# STM32H7A3xx register map
File version: 1.0
Registers are 32-bit, access not given, reset 0x0 unless marked. A register's access mark holds for its fields unless they carry their own. Offsets are from the block's base; [hi:lo] are bit positions; {n}, {i} and the like mark numbered series.

## OPAMP1
Base 0x40009000
Same registers: OPAMP2 0x40009010
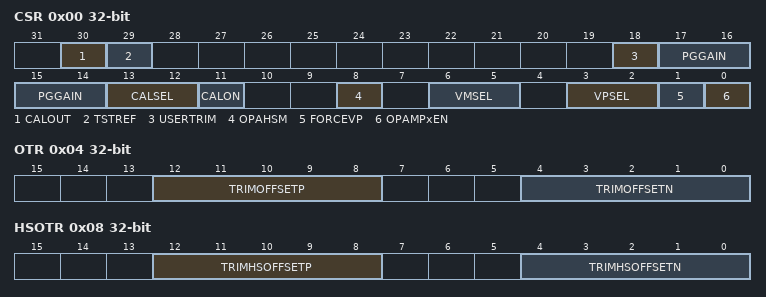
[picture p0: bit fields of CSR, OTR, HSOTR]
0x00 CSR
  [30] CALOUT, [29] TSTREF, [18] USERTRIM, [17:14] PGGAIN, [13:12] CALSEL, [11] CALON, [8] OPAHSM, [6:5] VMSEL, [3:2] VPSEL, [1] FORCEVP, [0] OPAMPxEN
0x04 OTR
  [12:8] TRIMOFFSETP, [4:0] TRIMOFFSETN
0x08 HSOTR
  [12:8] TRIMHSOFFSETP, [4:0] TRIMHSOFFSETN

## MDIOS
Base 0x40009400
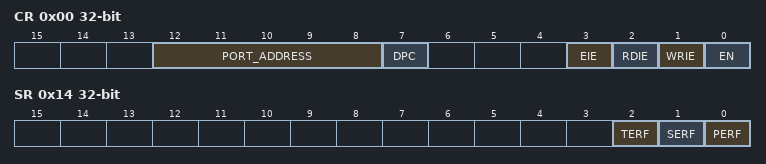
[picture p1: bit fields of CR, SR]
0x00 CR
  [12:8] PORT_ADDRESS, [7] DPC, [3] EIE, [2] RDIE, [1] WRIE, [0] EN
0x04 WRFR
0x08 CWRFR
0x0C RDFR
0x10 CRDFR
0x14 SR
  [2] TERF, [1] SERF, [0] PERF
0x18 CLRFR
{0x100+4i} DINR{i} (i=0..31)
{0x180+4i} DOUTR{i} (i=0..31)

## FDCAN1
Base 0x4000A000
Same registers: FDCAN2 0x4000A400
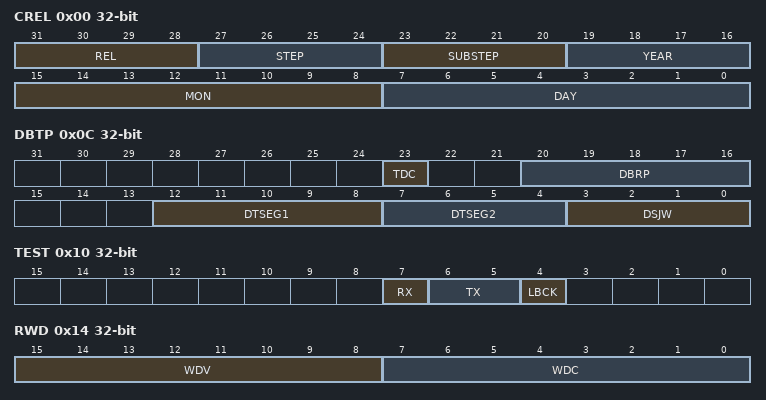
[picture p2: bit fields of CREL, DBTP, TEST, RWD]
0x00 CREL
  [31:28] REL, [27:24] STEP, [23:20] SUBSTEP, [19:16] YEAR, [15:8] MON, [7:0] DAY
0x04 ENDN
  [31:0] ETV
0x0C DBTP
  [23] TDC, [20:16] DBRP, [12:8] DTSEG1, [7:4] DTSEG2, [3:0] DSJW
0x10 TEST
  [7] RX, [6:5] TX, [4] LBCK
0x14 RWD
  [15:8] WDV, [7:0] WDC
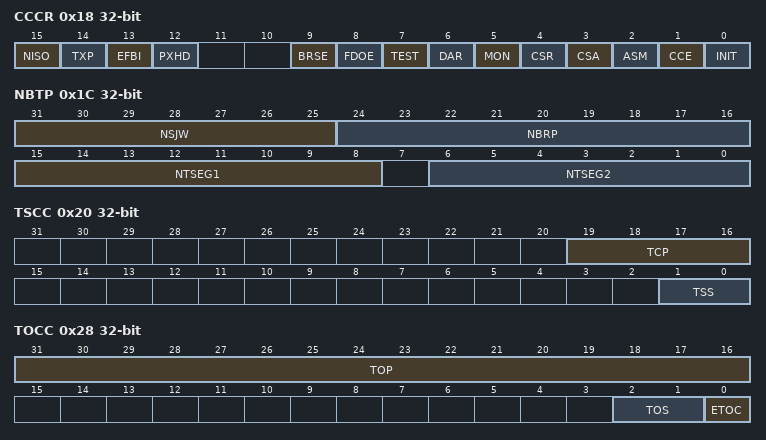
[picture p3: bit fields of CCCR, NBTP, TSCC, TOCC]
0x18 CCCR
  [15] NISO, [14] TXP, [13] EFBI, [12] PXHD, [9] BRSE, [8] FDOE, [7] TEST, [6] DAR, [5] MON, [4] CSR, [3] CSA, [2] ASM, [1] CCE, [0] INIT
0x1C NBTP
  [31:25] NSJW, [24:16] NBRP, [15:8] NTSEG1, [6:0] NTSEG2
0x20 TSCC
  [19:16] TCP, [1:0] TSS
0x24 TSCV
  [15:0] TSC
0x28 TOCC
  [31:16] TOP, [2:1] TOS, [0] ETOC
0x2C TOCV
  [15:0] TOC
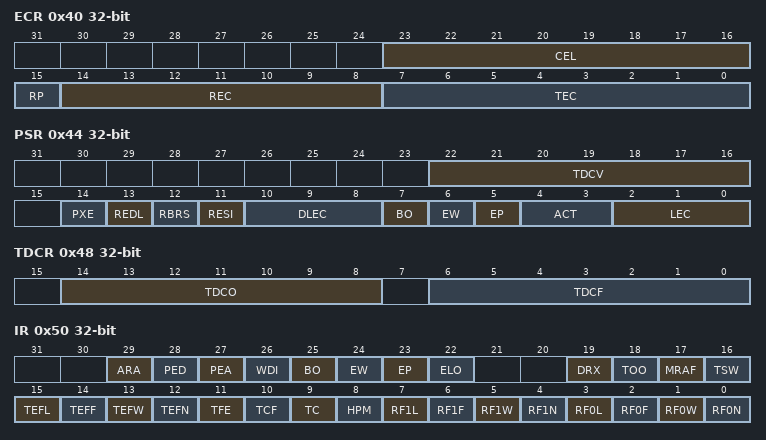
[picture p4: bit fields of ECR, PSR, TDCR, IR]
0x40 ECR
  [23:16] CEL, [15] RP, [14:8] REC, [7:0] TEC
0x44 PSR
  [22:16] TDCV, [14] PXE, [13] REDL, [12] RBRS, [11] RESI, [10:8] DLEC, [7] BO, [6] EW, [5] EP, [4:3] ACT, [2:0] LEC
0x48 TDCR
  [14:8] TDCO, [6:0] TDCF
0x50 IR
  [29] ARA, [28] PED, [27] PEA, [26] WDI, [25] BO, [24] EW, [23] EP, [22] ELO, [19] DRX, [18] TOO, [17] MRAF, [16] TSW, [15] TEFL, [14] TEFF, [13] TEFW, [12] TEFN, [11] TFE, [10] TCF, [9] TC, [8] HPM, [7] RF1L, [6] RF1F, [5] RF1W, [4] RF1N, [3] RF0L, [2] RF0F, [1] RF0W, [0] RF0N
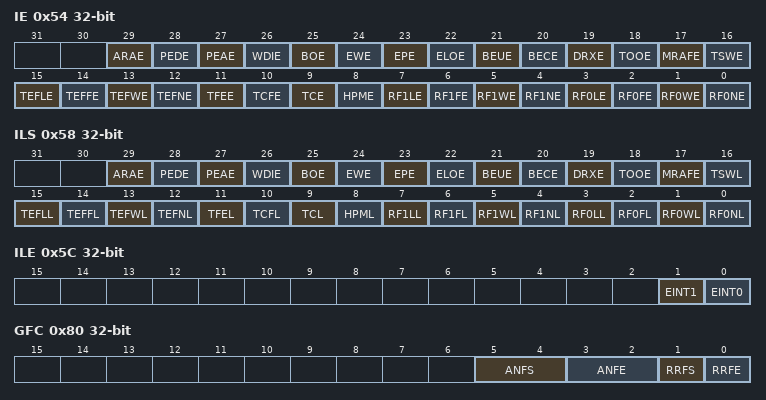
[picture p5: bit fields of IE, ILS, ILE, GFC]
0x54 IE
  [29] ARAE, [28] PEDE, [27] PEAE, [26] WDIE, [25] BOE, [24] EWE, [23] EPE, [22] ELOE, [21] BEUE, [20] BECE, [19] DRXE, [18] TOOE, [17] MRAFE, [16] TSWE, [15] TEFLE, [14] TEFFE, [13] TEFWE, [12] TEFNE, [11] TFEE, [10] TCFE, [9] TCE, [8] HPME, [7] RF1LE, [6] RF1FE, [5] RF1WE, [4] RF1NE, [3] RF0LE, [2] RF0FE, [1] RF0WE, [0] RF0NE
0x58 ILS
  [29] ARAE, [28] PEDE, [27] PEAE, [26] WDIE, [25] BOE, [24] EWE, [23] EPE, [22] ELOE, [21] BEUE, [20] BECE, [19] DRXE, [18] TOOE, [17] MRAFE, [16] TSWL, [15] TEFLL, [14] TEFFL, [13] TEFWL, [12] TEFNL, [11] TFEL, [10] TCFL, [9] TCL, [8] HPML, [7] RF1LL, [6] RF1FL, [5] RF1WL, [4] RF1NL, [3] RF0LL, [2] RF0FL, [1] RF0WL, [0] RF0NL
0x5C ILE
  [1] EINT1, [0] EINT0
0x80 GFC
  [5:4] ANFS, [3:2] ANFE, [1] RRFS, [0] RRFE
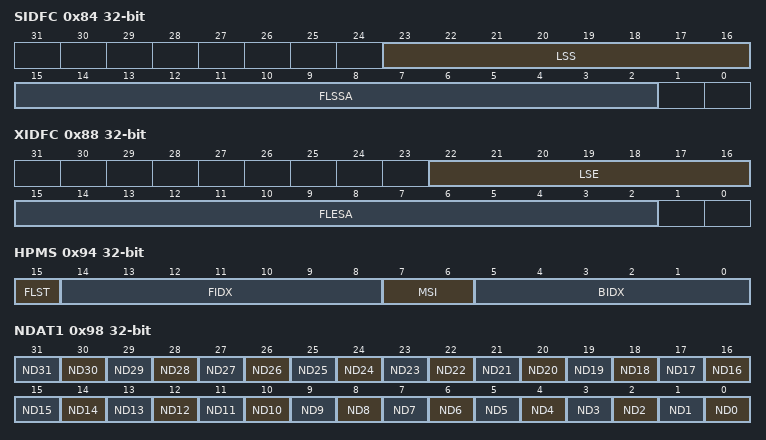
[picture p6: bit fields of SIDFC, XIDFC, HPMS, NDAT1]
0x84 SIDFC
  [23:16] LSS, [15:2] FLSSA
0x88 XIDFC
  [22:16] LSE, [15:2] FLESA
0x90 XIDAM
  [28:0] EIDM
0x94 HPMS
  [15] FLST, [14:8] FIDX, [7:6] MSI, [5:0] BIDX
0x98 NDAT1
  [n] ND{n} (n=0..31)
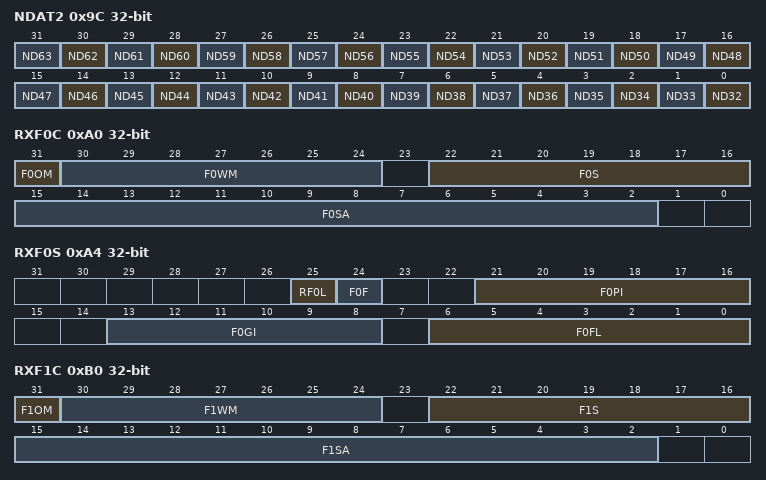
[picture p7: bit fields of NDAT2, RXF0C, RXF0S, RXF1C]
0x9C NDAT2
  [n-32] ND{n} (n=32..63)
0xA0 RXF0C
  [31] F0OM, [30:24] F0WM, [22:16] F0S, [15:2] F0SA
0xA4 RXF0S
  [25] RF0L, [24] F0F, [21:16] F0PI, [13:8] F0GI, [6:0] F0FL
0xA8 RXF0A
  [5:0] F0AI
0xAC RXBC
  [15:2] RBSA
0xB0 RXF1C
  [31] F1OM, [30:24] F1WM, [22:16] F1S, [15:2] F1SA
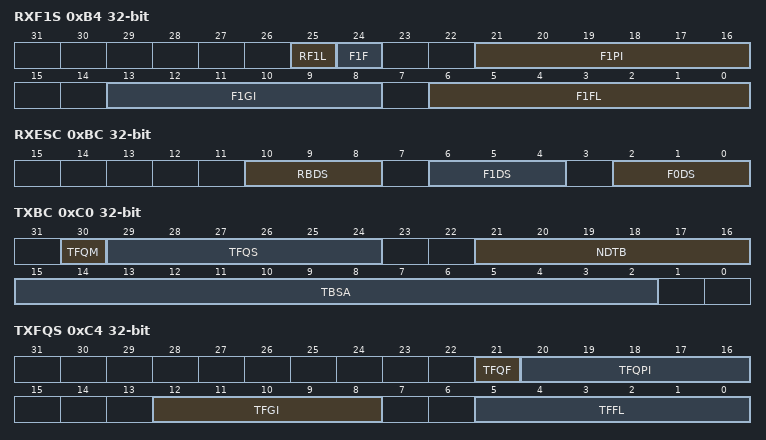
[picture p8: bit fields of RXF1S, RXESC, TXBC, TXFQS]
0xB4 RXF1S
  [25] RF1L, [24] F1F, [21:16] F1PI, [13:8] F1GI, [6:0] F1FL
0xB8 RXF1A
  [5:0] F1AI
0xBC RXESC
  [10:8] RBDS, [6:4] F1DS, [2:0] F0DS
0xC0 TXBC
  [30] TFQM, [29:24] TFQS, [21:16] NDTB, [15:2] TBSA
0xC4 TXFQS
  [21] TFQF, [20:16] TFQPI, [12:8] TFGI, [5:0] TFFL
0xC8 TXESC
  [2:0] TBDS
0xCC TXBRP
  [31:0] TRP
0xD0 TXBAR
  [31:0] AR
0xD4 TXBCR
  [31:0] CR
0xD8 TXBTO
  [31:0] TO
0xDC TXBCF
  [31:0] CF
0xE0 TXBTIE
  [31:0] TIE
0xE4 TXBCIE
  [31:0] CFIE
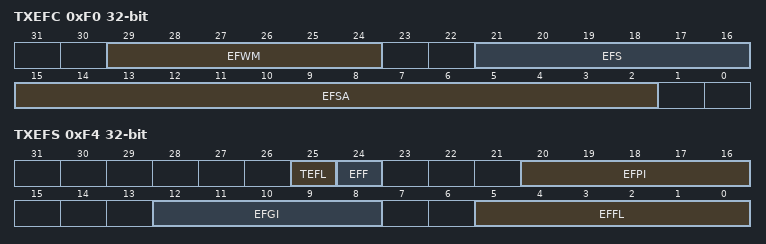
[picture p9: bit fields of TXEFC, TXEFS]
0xF0 TXEFC
  [29:24] EFWM, [21:16] EFS, [15:2] EFSA
0xF4 TXEFS
  [25] TEFL, [24] EFF, [20:16] EFPI, [12:8] EFGI, [5:0] EFFL
0xF8 TXEFA
  [4:0] EFAI

## FDCAN_CCU
Base 0x4000A800
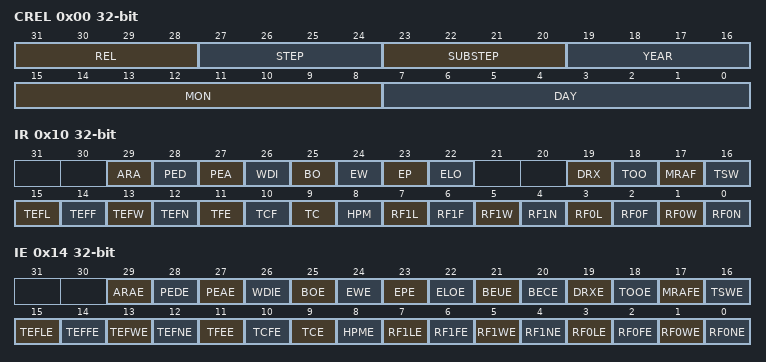
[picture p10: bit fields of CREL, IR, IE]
0x00 CREL
  [31:28] REL, [27:24] STEP, [23:20] SUBSTEP, [19:16] YEAR, [15:8] MON, [7:0] DAY
0x04 CCFG
0x08 CSTAT
0x0C CWD
0x10 IR
  [29] ARA, [28] PED, [27] PEA, [26] WDI, [25] BO, [24] EW, [23] EP, [22] ELO, [19] DRX, [18] TOO, [17] MRAF, [16] TSW, [15] TEFL, [14] TEFF, [13] TEFW, [12] TEFN, [11] TFE, [10] TCF, [9] TC, [8] HPM, [7] RF1L, [6] RF1F, [5] RF1W, [4] RF1N, [3] RF0L, [2] RF0F, [1] RF0W, [0] RF0N
0x14 IE
  [29] ARAE, [28] PEDE, [27] PEAE, [26] WDIE, [25] BOE, [24] EWE, [23] EPE, [22] ELOE, [21] BEUE, [20] BECE, [19] DRXE, [18] TOOE, [17] MRAFE, [16] TSWE, [15] TEFLE, [14] TEFFE, [13] TEFWE, [12] TEFNE, [11] TFEE, [10] TCFE, [9] TCE, [8] HPME, [7] RF1LE, [6] RF1FE, [5] RF1WE, [4] RF1NE, [3] RF0LE, [2] RF0FE, [1] RF0WE, [0] RF0NE
